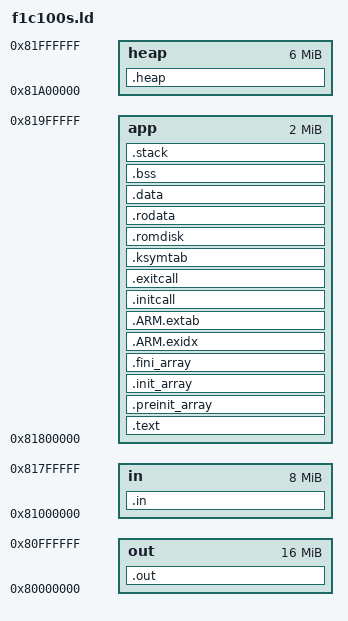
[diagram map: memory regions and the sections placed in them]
OUTPUT_FORMAT("elf32-littlearm", "elf32-bigarm", "elf32-littlearm")
OUTPUT_ARCH(arm)
ENTRY(_start)

STACK_UND_SIZE = 0x10000;
STACK_ABT_SIZE = 0x10000;
STACK_IRQ_SIZE = 0x10000;
STACK_FIQ_SIZE = 0x10000;
STACK_SRV_SIZE = 0x40000;

MEMORY
{
	out		: org = 0x80000000, len = 16M
	in		: org = 0x81000000, len = 8M
	app		: org = 0x81800000, len = 2M
	heap	: org = 0x81A00000, len = 6M
}

SECTIONS
{
	.out ALIGN(8) (NOLOAD) :
	{
		PROVIDE(__out_start = ORIGIN(out));
		PROVIDE(__out_end = ORIGIN(out) + LENGTH(out));
	} > out

	.in ALIGN(8) (NOLOAD) :
	{
		PROVIDE(__in_start = ORIGIN(in));
		PROVIDE(__in_end = ORIGIN(in) + LENGTH(in));
	} > in

	.text :
	{
		PROVIDE(__image_start = .);
		PROVIDE(__text_start = .);
		PROVIDE(__spl_start = .);
		build/boot/start.o (.text*)
		build/boot/sys-uart.o (.text*)
		build/boot/sys-clock.o (.text*)
		build/boot/sys-dram.o (.text*)
		build/boot/sys-mmu.o (.text*)
		build/boot/sys-spiflash.o (.text*)
		build/boot/sys-copyself.o (.text*)
		build/boot/sys-crypt.o (.text*)
		build/lib/memcpy.o (.text*)
		build/lib/memset.o (.text*)
		build/lib/strlen.o (.text*)
		build/driver/gpio.o (.text*)
		build/driver/spi.o (.text*)
		build/driver/ccu.o (.text*)
		PROVIDE(__spl_end = .);
		*(.text*)
		*(.init.text)
		*(.exit.text)
		*(.glue*)
		*(.note.gnu.build-id)
		PROVIDE(__text_end = .);
	} > app
	PROVIDE(__spl_size = __spl_end - __spl_start);
	
	.preinit_array     :
	{
		PROVIDE_HIDDEN (__preinit_array_start = .);
		KEEP (*(.preinit_array*))
		PROVIDE_HIDDEN (__preinit_array_end = .);
	} > app

	.init_array :
	{
		PROVIDE_HIDDEN (__init_array_start = .);
		KEEP (*(SORT(.init_array.*)))
		KEEP (*(.init_array*))
		PROVIDE_HIDDEN (__init_array_end = .);
	} > app

	.fini_array :
	{
		PROVIDE_HIDDEN (__fini_array_start = .);
		KEEP (*(SORT(.fini_array.*)))
		KEEP (*(.fini_array*))
		PROVIDE_HIDDEN (__fini_array_end = .);
	} > app

	.ARM.exidx ALIGN(8) :
	{
		PROVIDE (__exidx_start = .);
		*(.ARM.exidx*)
		PROVIDE (__exidx_end = .);
	} > app

	.ARM.extab ALIGN(8) :
	{
		PROVIDE (__extab_start = .);
		*(.ARM.extab*)
		PROVIDE (__extab_end = .);
	} > app

	.initcall ALIGN(8) :
	{
		PROVIDE(__initcall_start = .);
		KEEP(*(.initcall_0.text))
		KEEP(*(.initcall_1.text))
		KEEP(*(.initcall_2.text))
		KEEP(*(.initcall_3.text))
		KEEP(*(.initcall_4.text))
		KEEP(*(.initcall_5.text))
		KEEP(*(.initcall_6.text))
		KEEP(*(.initcall_7.text))
		KEEP(*(.initcall_8.text))
		KEEP(*(.initcall_9.text))
		PROVIDE(__initcall_end = .);
	} > app

	.exitcall ALIGN(8) :
	{
		PROVIDE(__exitcall_start = .);
		KEEP(*(.exitcall_9.text))
		KEEP(*(.exitcall_8.text))
		KEEP(*(.exitcall_7.text))
		KEEP(*(.exitcall_6.text))
		KEEP(*(.exitcall_5.text))
		KEEP(*(.exitcall_4.text))
		KEEP(*(.exitcall_3.text))
		KEEP(*(.exitcall_2.text))
		KEEP(*(.exitcall_1.text))
		KEEP(*(.exitcall_0.text))
		PROVIDE(__exitcall_end = .);
	} > app

	.ksymtab ALIGN(16) :
	{
		PROVIDE(__ksymtab_start = .);
		KEEP(*(.ksymtab.text))
		PROVIDE(__ksymtab_end = .);
	} > app

	.romdisk ALIGN(8) :
	{
		PROVIDE(__romdisk_start = .);
		KEEP(*(.romdisk))
		PROVIDE(__romdisk_end = .);
	} > app

	.rodata ALIGN(8) :
	{
		PROVIDE(__rodata_start = .);
		*(SORT_BY_ALIGNMENT(SORT_BY_NAME(.rodata*)))
		PROVIDE(__rodata_end = .);
	} > app

	.data ALIGN(8) :
	{
		PROVIDE(__data_start = .);	
		*(.data*)
		. = ALIGN(8);
  		PROVIDE(__data_end = .);
		PROVIDE(__image_end = .);
	} > app

	.bss ALIGN(8) (NOLOAD) :
	{
		PROVIDE(__bss_start = .);
		*(.bss*)
		*(.sbss*)
		*(COMMON)
		. = ALIGN(8);
		PROVIDE(__bss_end = .);
	} > app

	.stack ALIGN(8) (NOLOAD) :
	{
		PROVIDE(__stack_start = .);
		PROVIDE(__stack_und_start = .);
		. += STACK_UND_SIZE;
		PROVIDE(__stack_und_end = .);
		. = ALIGN(8);
		PROVIDE(__stack_abt_start = .);
		. += STACK_ABT_SIZE;
		PROVIDE(__stack_abt_end = .);
		. = ALIGN(8);
		PROVIDE(__stack_irq_start = .);
		. += STACK_IRQ_SIZE;
		PROVIDE(__stack_irq_end = .);
		. = ALIGN(8);
		PROVIDE(__stack_fiq_start = .);
		. += STACK_FIQ_SIZE;
		PROVIDE(__stack_fiq_end = .);
		. = ALIGN(8);
		PROVIDE(__stack_srv_start = .);
		. += STACK_SRV_SIZE;
		PROVIDE(__stack_srv_end = .);
		. = ALIGN(8);
		PROVIDE(__stack_end = .);
	} > app

	.heap ALIGN(8) (NOLOAD) :
	{
		PROVIDE(__heap_start = ORIGIN(heap));
		PROVIDE(__heap_end = ORIGIN(heap) + LENGTH(heap));
	} > heap

	.stab 0 : { *(.stab) }
	.stabstr 0 : { *(.stabstr) }
	.stab.excl 0 : { *(.stab.excl) }
	.stab.exclstr 0 : { *(.stab.exclstr) }
	.stab.index 0 : { *(.stab.index) }
	.stab.indexstr 0 : { *(.stab.indexstr) }
	.comment 0 : { *(.comment) }
	.debug_abbrev 0 : { *(.debug_abbrev) }
	.debug_info 0 : { *(.debug_info) }
	.debug_line 0 : { *(.debug_line) }
	.debug_pubnames 0 : { *(.debug_pubnames) }
	.debug_aranges 0 : { *(.debug_aranges) }
}
